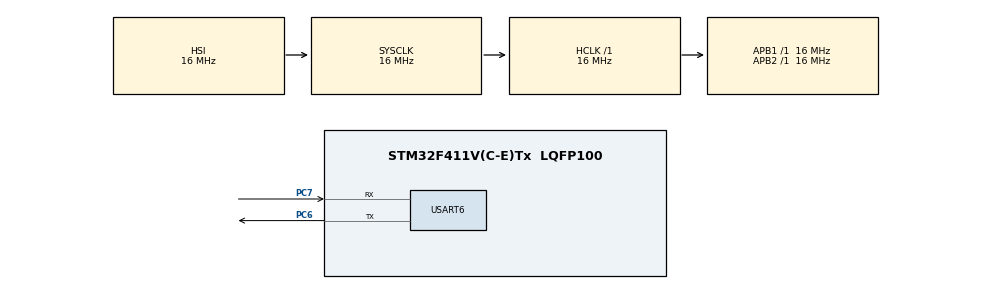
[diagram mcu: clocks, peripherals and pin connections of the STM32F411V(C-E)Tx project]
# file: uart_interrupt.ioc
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Mcu.Family=STM32F4
Mcu.Name=STM32F411V(C-E)Tx
Mcu.Package=LQFP100
NVIC.PriorityGroup=NVIC_PRIORITYGROUP_4
NVIC.USART6_IRQn=true\:0\:0\:false\:false\:true\:true\:true\:true
PA13.Mode=Serial_Wire
PA13.Signal=SYS_JTMS-SWDIO
PA14.Mode=Serial_Wire
PA14.Signal=SYS_JTCK-SWCLK
PC6.Mode=Asynchronous
PC6.Signal=USART6_TX
PC7.Mode=Asynchronous
PC7.Signal=USART6_RX
ProjectManager.HeapSize=0x200
ProjectManager.StackSize=0x400
ProjectManager.TargetToolchain=STM32CubeIDE
RCC.AHBFreq_Value=16000000
RCC.APB1Freq_Value=16000000
RCC.APB2Freq_Value=16000000
RCC.CortexFreq_Value=16000000
RCC.HSE_VALUE=25000000
RCC.HSI_VALUE=16000000
RCC.LSE_VALUE=32768
RCC.SYSCLKFreq_VALUE=16000000
RCC.VCOOutputFreq_Value=192000000
USART6.VirtualMode=VM_ASYNC
board=custom

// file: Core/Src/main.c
/* USER CODE BEGIN Header */
/**
  ******************************************************************************
  * @file           : main.c
  * @brief          : Main program body
  ******************************************************************************
  * @attention
  *
  * Copyright (c) 2024 STMicroelectronics.
  * All rights reserved.
  *
  * This software is licensed under terms that can be found in the LICENSE file
  * in the root directory of this software component.
  * If no LICENSE file comes with this software, it is provided AS-IS.
  *
  ******************************************************************************
  */
/* USER CODE END Header */
#include "main.h"

UART_HandleTypeDef huart6;

void SystemClock_Config(void);
static void MX_GPIO_Init(void);
static void MX_USART6_UART_Init(void);

/* USER CODE BEGIN 0 */
uint8_t rx_data[1] = {0};
uint8_t tx_data[1] = {0};

/* USER CODE END 0 */

int main(void)
{

  /* MCU Configuration--------------------------------------------------------*/

  /* Reset of all peripherals, Initializes the Flash interface and the Systick. */
  HAL_Init();

  /* Configure the system clock */
  SystemClock_Config();

  /* Initialize all configured peripherals */
  MX_GPIO_Init();
  MX_USART6_UART_Init();
  /* USER CODE BEGIN 2 */
  HAL_UART_Receive_IT(&huart6, rx_data, sizeof(rx_data));

  /* USER CODE END 2 */

  /* Infinite loop */
  while (1)
  {

  }
}

void SystemClock_Config(void)
{
  RCC_OscInitTypeDef RCC_OscInitStruct = {0};
  RCC_ClkInitTypeDef RCC_ClkInitStruct = {0};

  /** Configure the main internal regulator output voltage
  */
  __HAL_RCC_PWR_CLK_ENABLE();
  __HAL_PWR_VOLTAGESCALING_CONFIG(PWR_REGULATOR_VOLTAGE_SCALE1);

  /** Initializes the RCC Oscillators according to the specified parameters
  * in the RCC_OscInitTypeDef structure.
  */
  RCC_OscInitStruct.OscillatorType = RCC_OSCILLATORTYPE_HSI;
  RCC_OscInitStruct.HSIState = RCC_HSI_ON;
  RCC_OscInitStruct.HSICalibrationValue = RCC_HSICALIBRATION_DEFAULT;
  RCC_OscInitStruct.PLL.PLLState = RCC_PLL_NONE;
  if (HAL_RCC_OscConfig(&RCC_OscInitStruct) != HAL_OK)
  {
    Error_Handler();
  }

  /** Initializes the CPU, AHB and APB buses clocks
  */
  RCC_ClkInitStruct.ClockType = RCC_CLOCKTYPE_HCLK|RCC_CLOCKTYPE_SYSCLK
                              |RCC_CLOCKTYPE_PCLK1|RCC_CLOCKTYPE_PCLK2;
  RCC_ClkInitStruct.SYSCLKSource = RCC_SYSCLKSOURCE_HSI;
  RCC_ClkInitStruct.AHBCLKDivider = RCC_SYSCLK_DIV1;
  RCC_ClkInitStruct.APB1CLKDivider = RCC_HCLK_DIV1;
  RCC_ClkInitStruct.APB2CLKDivider = RCC_HCLK_DIV1;

  if (HAL_RCC_ClockConfig(&RCC_ClkInitStruct, FLASH_LATENCY_0) != HAL_OK)
  {
    Error_Handler();
  }
}

static void MX_USART6_UART_Init(void)
{

  huart6.Instance = USART6;
  huart6.Init.BaudRate = 115200;
  huart6.Init.WordLength = UART_WORDLENGTH_8B;
  huart6.Init.StopBits = UART_STOPBITS_1;
  huart6.Init.Parity = UART_PARITY_NONE;
  huart6.Init.Mode = UART_MODE_TX_RX;
  huart6.Init.HwFlowCtl = UART_HWCONTROL_NONE;
  huart6.Init.OverSampling = UART_OVERSAMPLING_16;
  if (HAL_UART_Init(&huart6) != HAL_OK)
  {
    Error_Handler();
  }

}

static void MX_GPIO_Init(void)
{
  GPIO_InitTypeDef GPIO_InitStruct = {0};

  /* GPIO Ports Clock Enable */
  __HAL_RCC_GPIOE_CLK_ENABLE();
  __HAL_RCC_GPIOC_CLK_ENABLE();
  __HAL_RCC_GPIOH_CLK_ENABLE();
  __HAL_RCC_GPIOA_CLK_ENABLE();
  __HAL_RCC_GPIOB_CLK_ENABLE();
  __HAL_RCC_GPIOD_CLK_ENABLE();

  /*Configure GPIO pins : PE2 PE3 PE4 PE5
                           PE6 PE7 PE8 PE9
                           PE10 PE11 PE12 PE13
                           PE14 PE15 PE0 PE1 */
  GPIO_InitStruct.Pin = GPIO_PIN_2|GPIO_PIN_3|GPIO_PIN_4|GPIO_PIN_5
                          |GPIO_PIN_6|GPIO_PIN_7|GPIO_PIN_8|GPIO_PIN_9
                          |GPIO_PIN_10|GPIO_PIN_11|GPIO_PIN_12|GPIO_PIN_13
                          |GPIO_PIN_14|GPIO_PIN_15|GPIO_PIN_0|GPIO_PIN_1;
  GPIO_InitStruct.Mode = GPIO_MODE_ANALOG;
  GPIO_InitStruct.Pull = GPIO_NOPULL;
  HAL_GPIO_Init(GPIOE, &GPIO_InitStruct);

  /*Configure GPIO pins : PC13 PC14 PC15 PC0
                           PC1 PC2 PC3 PC4
                           PC5 PC8 PC9 PC10
                           PC11 PC12 */
  GPIO_InitStruct.Pin = GPIO_PIN_13|GPIO_PIN_14|GPIO_PIN_15|GPIO_PIN_0
                          |GPIO_PIN_1|GPIO_PIN_2|GPIO_PIN_3|GPIO_PIN_4
                          |GPIO_PIN_5|GPIO_PIN_8|GPIO_PIN_9|GPIO_PIN_10
                          |GPIO_PIN_11|GPIO_PIN_12;
  GPIO_InitStruct.Mode = GPIO_MODE_ANALOG;
  GPIO_InitStruct.Pull = GPIO_NOPULL;
  HAL_GPIO_Init(GPIOC, &GPIO_InitStruct);

  /*Configure GPIO pins : PH0 PH1 */
  GPIO_InitStruct.Pin = GPIO_PIN_0|GPIO_PIN_1;
  GPIO_InitStruct.Mode = GPIO_MODE_ANALOG;
  GPIO_InitStruct.Pull = GPIO_NOPULL;
  HAL_GPIO_Init(GPIOH, &GPIO_InitStruct);

  /*Configure GPIO pins : PA0 PA1 PA2 PA3
                           PA4 PA5 PA6 PA7
                           PA8 PA9 PA10 PA11
                           PA12 PA15 */
  GPIO_InitStruct.Pin = GPIO_PIN_0|GPIO_PIN_1|GPIO_PIN_2|GPIO_PIN_3
                          |GPIO_PIN_4|GPIO_PIN_5|GPIO_PIN_6|GPIO_PIN_7
                          |GPIO_PIN_8|GPIO_PIN_9|GPIO_PIN_10|GPIO_PIN_11
                          |GPIO_PIN_12|GPIO_PIN_15;
  GPIO_InitStruct.Mode = GPIO_MODE_ANALOG;
  GPIO_InitStruct.Pull = GPIO_NOPULL;
  HAL_GPIO_Init(GPIOA, &GPIO_InitStruct);

  /*Configure GPIO pins : PB0 PB1 PB2 PB10
                           PB12 PB13 PB14 PB15
                           PB3 PB4 PB5 PB6
                           PB7 PB8 PB9 */
  GPIO_InitStruct.Pin = GPIO_PIN_0|GPIO_PIN_1|GPIO_PIN_2|GPIO_PIN_10
                          |GPIO_PIN_12|GPIO_PIN_13|GPIO_PIN_14|GPIO_PIN_15
                          |GPIO_PIN_3|GPIO_PIN_4|GPIO_PIN_5|GPIO_PIN_6
                          |GPIO_PIN_7|GPIO_PIN_8|GPIO_PIN_9;
  GPIO_InitStruct.Mode = GPIO_MODE_ANALOG;
  GPIO_InitStruct.Pull = GPIO_NOPULL;
  HAL_GPIO_Init(GPIOB, &GPIO_InitStruct);

  /*Configure GPIO pins : PD8 PD9 PD10 PD11
                           PD12 PD13 PD14 PD15
                           PD0 PD1 PD2 PD3
                           PD4 PD5 PD6 PD7 */
  GPIO_InitStruct.Pin = GPIO_PIN_8|GPIO_PIN_9|GPIO_PIN_10|GPIO_PIN_11
                          |GPIO_PIN_12|GPIO_PIN_13|GPIO_PIN_14|GPIO_PIN_15
                          |GPIO_PIN_0|GPIO_PIN_1|GPIO_PIN_2|GPIO_PIN_3
                          |GPIO_PIN_4|GPIO_PIN_5|GPIO_PIN_6|GPIO_PIN_7;
  GPIO_InitStruct.Mode = GPIO_MODE_ANALOG;
  GPIO_InitStruct.Pull = GPIO_NOPULL;
  HAL_GPIO_Init(GPIOD, &GPIO_InitStruct);

}

/* USER CODE BEGIN 4 */
void HAL_UART_RxCpltCallback(UART_HandleTypeDef *huart)
{
	if (huart->Instance == USART6)
	{
		tx_data[0] = rx_data[0];
		HAL_UART_Transmit(&huart6, (uint8_t *)tx_data, sizeof(tx_data), HAL_MAX_DELAY);
	}
	HAL_UART_Receive_IT(&huart6, (uint8_t *)rx_data, sizeof(rx_data));
}

/* USER CODE END 4 */

void Error_Handler(void)
{
  __disable_irq();
  while (1)
  {
  }
}
